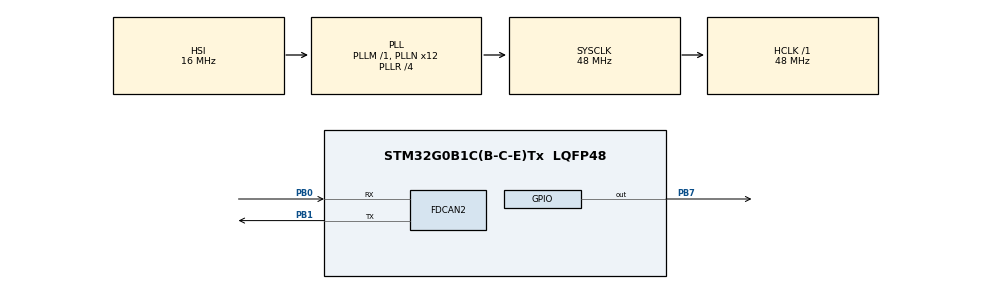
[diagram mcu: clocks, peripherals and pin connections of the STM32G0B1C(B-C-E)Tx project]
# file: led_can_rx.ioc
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FDCAN2.CalculateBaudRateNominal=500000
FDCAN2.CalculateTimeBitNominal=2000
FDCAN2.CalculateTimeQuantumNominal=125.0
FDCAN2.DataPrescaler=6
FDCAN2.DataTimeSeg1=13
FDCAN2.DataTimeSeg2=2
FDCAN2.ExtFiltersNbr=8
FDCAN2.NominalPrescaler=6
FDCAN2.NominalTimeSeg1=13
FDCAN2.StdFiltersNbr=28
Mcu.Family=STM32G0
Mcu.Name=STM32G0B1C(B-C-E)Tx
Mcu.Package=LQFP48
PB0.Mode=FDCAN_Activate
PB0.Signal=FDCAN2_RX
PB1.Mode=FDCAN_Activate
PB1.Signal=FDCAN2_TX
PB7.Signal=GPIO_Output
ProjectManager.HeapSize=0x200
ProjectManager.StackSize=0x400
ProjectManager.TargetToolchain=STM32CubeIDE
RCC.ADCFreq_Value=48000000
RCC.AHBFreq_Value=48000000
RCC.CortexFreq_Value=48000000
RCC.EXTERNAL_CLOCK_VALUE=48000
RCC.HCLKFreq_Value=48000000
RCC.HSE_VALUE=8000000
RCC.HSI48_VALUE=48000000
RCC.HSI_VALUE=16000000
RCC.LSE_VALUE=32768
RCC.PLLN=12
RCC.PLLR=RCC_PLLR_DIV4
RCC.SYSCLKFreq_VALUE=48000000
RCC.SYSCLKSource=RCC_SYSCLKSOURCE_PLLCLK
RCC.USBFreq_Value=48000000
RCC.VCOOutputFreq_Value=192000000
board=custom

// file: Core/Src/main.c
/* USER CODE BEGIN Header */
/**
  ******************************************************************************
  * @file           : main.c
  * @brief          : Main program body
  ******************************************************************************
  * @attention
  *
  * Copyright (c) 2025 STMicroelectronics.
  * All rights reserved.
  *
  * This software is licensed under terms that can be found in the LICENSE file
  * in the root directory of this software component.
  * If no LICENSE file comes with this software, it is provided AS-IS.
  *
  ******************************************************************************
  */
/* USER CODE END Header */
#include "main.h"

FDCAN_HandleTypeDef hfdcan2;

void SystemClock_Config(void);
static void MX_GPIO_Init(void);
static void MX_FDCAN2_Init(void);

/* USER CODE BEGIN 0 */
FDCAN_RxHeaderTypeDef RxHeader;
uint8_t RxData[8];
/* USER CODE END 0 */

int main(void)
{

  /* MCU Configuration--------------------------------------------------------*/

  /* Reset of all peripherals, Initializes the Flash interface and the Systick. */
  HAL_Init();

  /* Configure the system clock */
  SystemClock_Config();

  /* Initialize all configured peripherals */
  MX_GPIO_Init();
  MX_FDCAN2_Init();
  /* USER CODE BEGIN 2 */

  if(HAL_FDCAN_Start(&hfdcan2))
  {
	  Error_Handler();
  }
  /* USER CODE END 2 */

  /* Infinite loop */
  while (1)
  {

	  if(HAL_FDCAN_GetRxFifoFillLevel(&hfdcan2, FDCAN_RX_FIFO0)>0)
	  {
		  if(HAL_FDCAN_GetRxMessage(&hfdcan2, FDCAN_RX_FIFO0, &RxHeader, RxData) == HAL_OK)
		  {
			  /*HAL_GPIO_TogglePin(GPIOB, GPIO_PIN_7);
			  HAL_Delay(200);
			  HAL_GPIO_TogglePin(GPIOB, GPIO_PIN_7);
		  	  */
			  if(RxData[0] == 1)
			  {
				  HAL_GPIO_WritePin(GPIOB, GPIO_PIN_7, GPIO_PIN_SET);
			  }
			  if(RxData[0] == 0)
			  {
				  HAL_GPIO_WritePin(GPIOB, GPIO_PIN_7, GPIO_PIN_RESET);
			  }
		  }
	  }
	  HAL_Delay(10);
  }
}

void SystemClock_Config(void)
{
  RCC_OscInitTypeDef RCC_OscInitStruct = {0};
  RCC_ClkInitTypeDef RCC_ClkInitStruct = {0};

  /** Configure the main internal regulator output voltage
  */
  HAL_PWREx_ControlVoltageScaling(PWR_REGULATOR_VOLTAGE_SCALE1);

  /** Initializes the RCC Oscillators according to the specified parameters
  * in the RCC_OscInitTypeDef structure.
  */
  RCC_OscInitStruct.OscillatorType = RCC_OSCILLATORTYPE_HSI;
  RCC_OscInitStruct.HSIState = RCC_HSI_ON;
  RCC_OscInitStruct.HSIDiv = RCC_HSI_DIV1;
  RCC_OscInitStruct.HSICalibrationValue = RCC_HSICALIBRATION_DEFAULT;
  RCC_OscInitStruct.PLL.PLLState = RCC_PLL_ON;
  RCC_OscInitStruct.PLL.PLLSource = RCC_PLLSOURCE_HSI;
  RCC_OscInitStruct.PLL.PLLM = RCC_PLLM_DIV1;
  RCC_OscInitStruct.PLL.PLLN = 12;
  RCC_OscInitStruct.PLL.PLLP = RCC_PLLP_DIV2;
  RCC_OscInitStruct.PLL.PLLQ = RCC_PLLQ_DIV2;
  RCC_OscInitStruct.PLL.PLLR = RCC_PLLR_DIV4;
  if (HAL_RCC_OscConfig(&RCC_OscInitStruct) != HAL_OK)
  {
    Error_Handler();
  }

  /** Initializes the CPU, AHB and APB buses clocks
  */
  RCC_ClkInitStruct.ClockType = RCC_CLOCKTYPE_HCLK|RCC_CLOCKTYPE_SYSCLK
                              |RCC_CLOCKTYPE_PCLK1;
  RCC_ClkInitStruct.SYSCLKSource = RCC_SYSCLKSOURCE_PLLCLK;
  RCC_ClkInitStruct.AHBCLKDivider = RCC_SYSCLK_DIV1;
  RCC_ClkInitStruct.APB1CLKDivider = RCC_HCLK_DIV1;

  if (HAL_RCC_ClockConfig(&RCC_ClkInitStruct, FLASH_LATENCY_1) != HAL_OK)
  {
    Error_Handler();
  }
}

static void MX_FDCAN2_Init(void)
{

  hfdcan2.Instance = FDCAN2;
  hfdcan2.Init.ClockDivider = FDCAN_CLOCK_DIV1;
  hfdcan2.Init.FrameFormat = FDCAN_FRAME_CLASSIC;
  hfdcan2.Init.Mode = FDCAN_MODE_NORMAL;
  hfdcan2.Init.AutoRetransmission = DISABLE;
  hfdcan2.Init.TransmitPause = DISABLE;
  hfdcan2.Init.ProtocolException = DISABLE;
  hfdcan2.Init.NominalPrescaler = 6;
  hfdcan2.Init.NominalSyncJumpWidth = 1;
  hfdcan2.Init.NominalTimeSeg1 = 13;
  hfdcan2.Init.NominalTimeSeg2 = 2;
  hfdcan2.Init.DataPrescaler = 6;
  hfdcan2.Init.DataSyncJumpWidth = 1;
  hfdcan2.Init.DataTimeSeg1 = 13;
  hfdcan2.Init.DataTimeSeg2 = 2;
  hfdcan2.Init.StdFiltersNbr = 28;
  hfdcan2.Init.ExtFiltersNbr = 8;
  hfdcan2.Init.TxFifoQueueMode = FDCAN_TX_FIFO_OPERATION;
  if (HAL_FDCAN_Init(&hfdcan2) != HAL_OK)
  {
    Error_Handler();
  }

}

static void MX_GPIO_Init(void)
{
  GPIO_InitTypeDef GPIO_InitStruct = {0};

  /* GPIO Ports Clock Enable */
  __HAL_RCC_GPIOB_CLK_ENABLE();

  /*Configure GPIO pin Output Level */
  HAL_GPIO_WritePin(GPIOB, GPIO_PIN_7, GPIO_PIN_RESET);

  /*Configure GPIO pin : PB7 */
  GPIO_InitStruct.Pin = GPIO_PIN_7;
  GPIO_InitStruct.Mode = GPIO_MODE_OUTPUT_PP;
  GPIO_InitStruct.Pull = GPIO_NOPULL;
  GPIO_InitStruct.Speed = GPIO_SPEED_FREQ_LOW;
  HAL_GPIO_Init(GPIOB, &GPIO_InitStruct);

}

void Error_Handler(void)
{
  __disable_irq();
  while (1)
  {
  }
}
